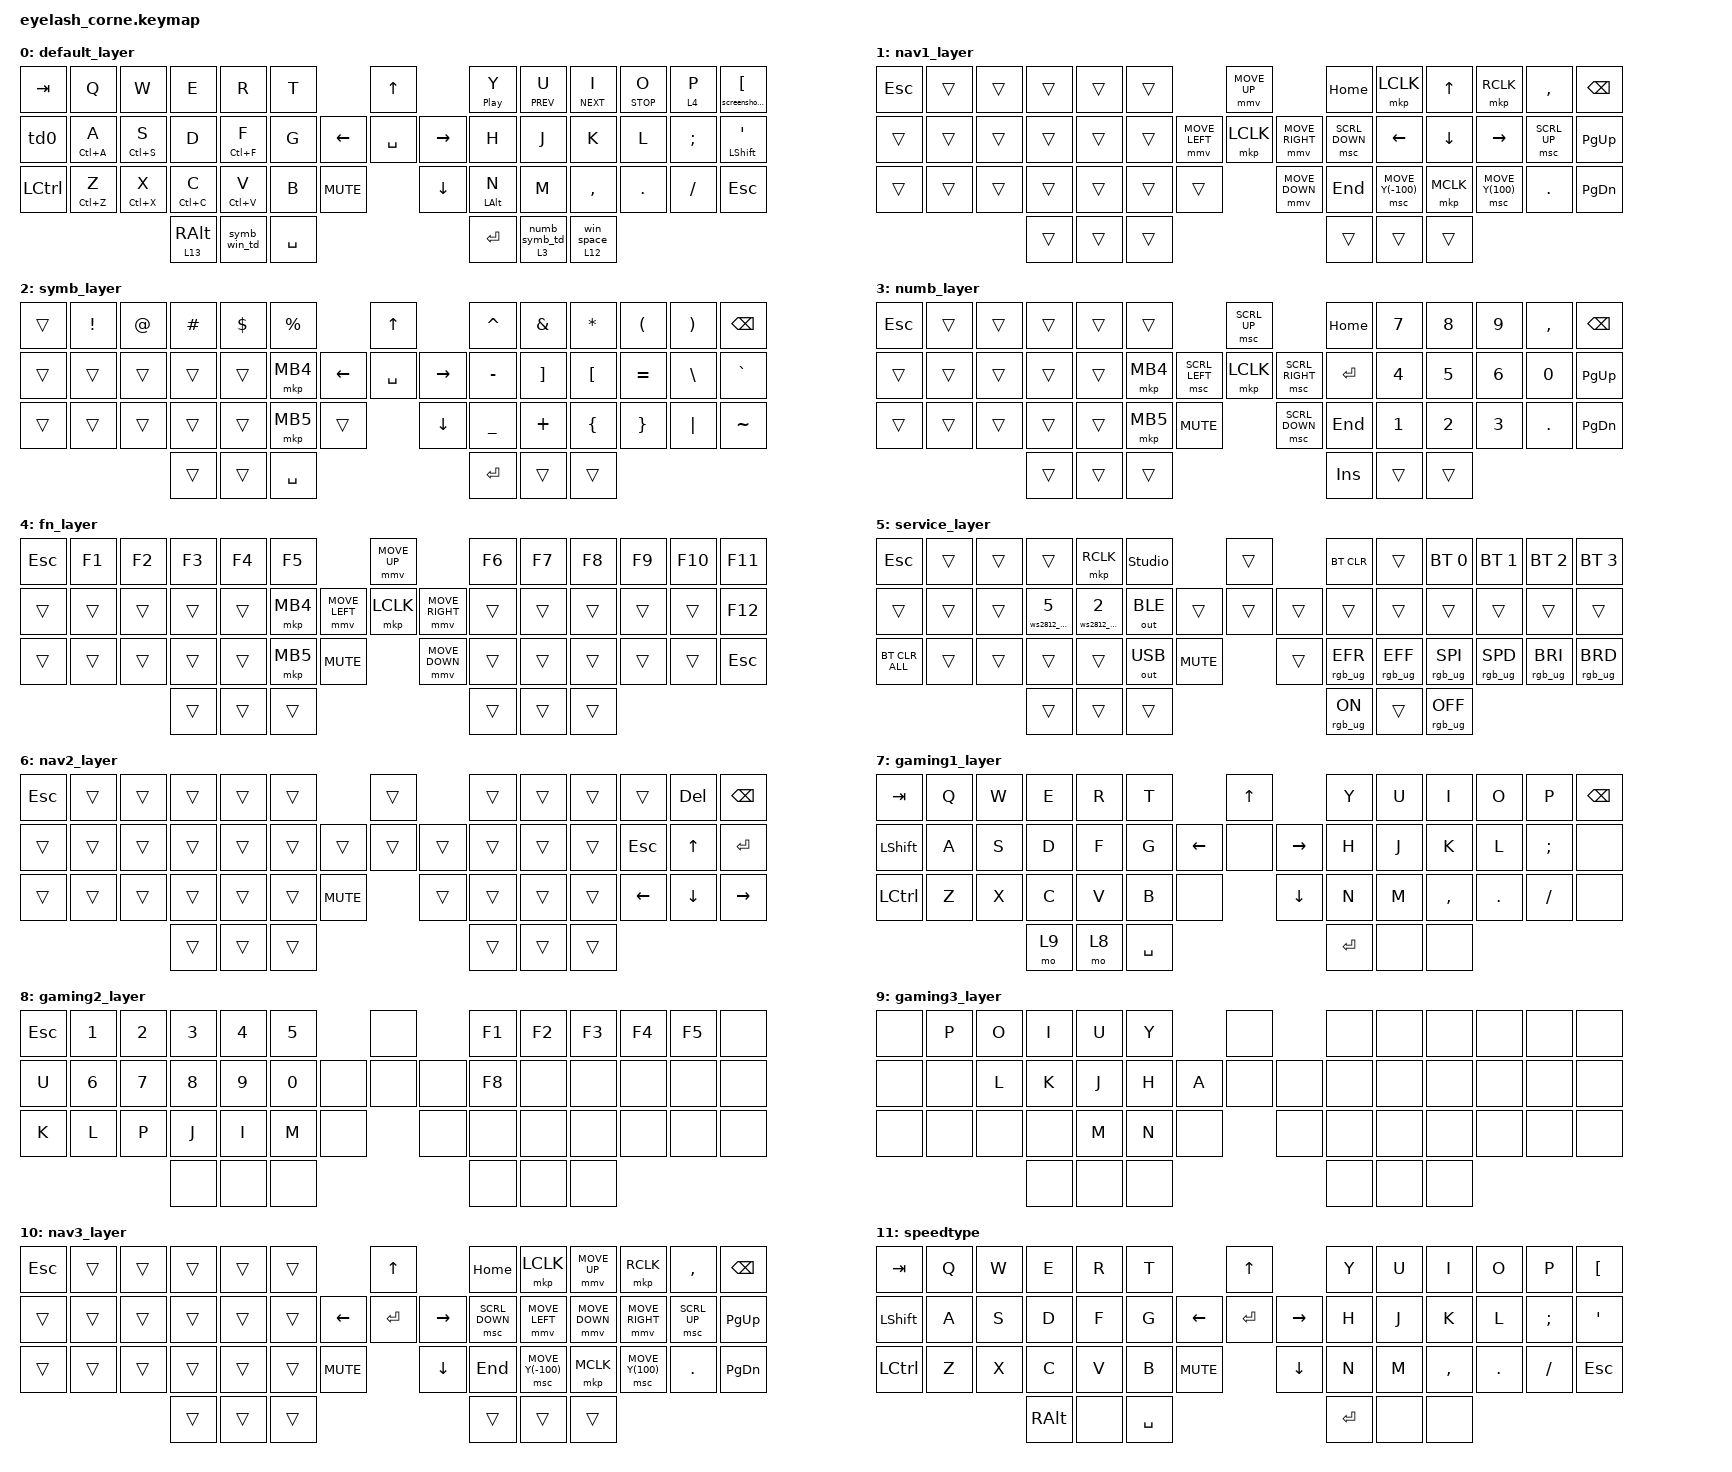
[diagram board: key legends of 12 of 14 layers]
#define ZMK_POINTING_DEFAULT_MOVE_VAL 1200
#define ZMK_POINTING_DEFAULT_SCRL_VAL 25

#include <input/processors.dtsi>
#include <zephyr/dt-bindings/input/input-event-codes.h>
#include <behaviors.dtsi>
#include <behaviors/ws2812_widget.dtsi>
#include <behaviors/ws2812_layer_sync.dtsi>
#include <dt-bindings/zmk/bt.h>
#include <dt-bindings/zmk/keys.h>
#include <dt-bindings/zmk/outputs.h>
#include <dt-bindings/zmk/pointing.h>
#include <dt-bindings/zmk/rgb.h>

&led_strip {
    chain-length = <42>;
};

&mmv_input_listener { input-processors = <&zip_xy_scaler 2 1>; };
&msc_input_listener { input-processors = <&zip_scroll_scaler 2 1>; };

&msc {
    acceleration-exponent = <1>;
    time-to-max-speed-ms = <100>;
    delay-ms = <0>;
};

&mmv {
    time-to-max-speed-ms = <500>;
    acceleration-exponent = <1>;
    trigger-period-ms = <16>;
};

/ {
    chosen {
        zmk,ws2812-widget = &led_strip;
    };

    behaviors {
        td0: td0 {
            compatible = "zmk,behavior-tap-dance";
            #binding-cells = <0>;
            bindings = <&kp LEFT_SHIFT>, <&kp CAPS>;
        };

        numb_symb_td: numb_symb_td {
            compatible = "zmk,behavior-tap-dance";
            #binding-cells = <0>;
            tapping-term-ms = <300>;
            bindings = <&tog 3>, <&tog 2>;
        };

        // Предпоследняя кнопка: Hold = слой цифр (3), Tap = tog цифры/символы
        thumb_num_sym_fn: thumb_num_sym_fn {
            compatible = "zmk,behavior-hold-tap";
            #binding-cells = <2>;
            flavor = "hold-preferred";
            tapping-term-ms = <200>;
            require-prior-idle-ms = <150>;
            bindings = <&mo>, <&numb_symb_td>;
        };

        // Последняя кнопка: Hold = nav2nolight (слой 12), Tap = Win+Space
        lang_nav2: lang_nav2 {
            compatible = "zmk,behavior-hold-tap";
            #binding-cells = <2>;
            flavor = "tap-preferred";
            tapping-term-ms = <220>;
            quick-tap-ms = <150>;
            bindings = <&mo>, <&win_space>;
        };

        nav2_double_tap: nav2_double_tap {
            compatible = "zmk,behavior-tap-dance";
            #binding-cells = <0>;
            tapping-term-ms = <300>;
            bindings = <&trans>, <&tog 6>;
        };

        speedtype_double_tap: speedtype_double_tap {
            compatible = "zmk,behavior-tap-dance";
            #binding-cells = <0>;
            tapping-term-ms = <300>;
            bindings = <&trans>, <&tog 11>;
        };

        kp_once: kp_once {
            compatible = "zmk,behavior-macro-one-param";
            #binding-cells = <1>;
            wait-ms = <0>;
            tap-ms = <0>;
            bindings = <&macro_param_1to1 &macro_press &kp 0>,
                       <&macro_param_1to1 &macro_release &kp 0>;
        };

        edit_ht: edit_ht {
            compatible = "zmk,behavior-hold-tap";
            #binding-cells = <2>;
            flavor = "tap-preferred";
            tapping-term-ms = <220>;
            quick-tap-ms = <150>;
            bindings = <&kp_once>, <&kp>;
        };

        media_ht: media_ht {
            compatible = "zmk,behavior-hold-tap";
            #binding-cells = <2>;
            flavor = "tap-preferred";
            tapping-term-ms = <200>;
            quick-tap-ms = <120>;
            bindings = <&kp>, <&kp>;
        };

        lang_alt: lang_alt {
            compatible = "zmk,behavior-hold-tap";
            #binding-cells = <2>;
            flavor = "tap-preferred";
            tapping-term-ms = <220>;
            quick-tap-ms = <150>;
            bindings = <&kp>, <&kp>;
        };

        // Вторая кнопка слева снизу: Hold = слой символов, Double tap = Windows
        symb_win_td: symb_win_td {
            compatible = "zmk,behavior-tap-dance";
            #binding-cells = <0>;
            tapping-term-ms = <300>;
            bindings = <&mo 2>, <&kp LGUI>;
        };

        // P: Hold = FN слой (4), Tap = буква P
        p_fn_ht: p_fn_ht {
            compatible = "zmk,behavior-hold-tap";
            #binding-cells = <2>;
            flavor = "hold-preferred";
            tapping-term-ms = <200>;
            bindings = <&mo>, <&kp>;
        };

        // Самая левая снизу: Hold = lefthand (13), Tap = RAlt
        lefthand_ht: lefthand_ht {
            compatible = "zmk,behavior-hold-tap";
            #binding-cells = <2>;
            flavor = "hold-preferred";
            tapping-term-ms = <200>;
            require-prior-idle-ms = <150>;
            bindings = <&mo>, <&kp>;
        };

        screenshot_win_shift_s: screenshot_win_shift_s {
            compatible = "zmk,behavior-macro";
            #binding-cells = <0>;
            wait-ms = <0>;
            tap-ms = <30>;
            bindings =
                <&macro_press &kp LGUI>,
                <&macro_press &kp LSHIFT>,
                <&macro_tap &kp S>,
                <&macro_release &kp LSHIFT>,
                <&macro_release &kp LGUI>;
        };

        lbkt_screenshot: lbkt_screenshot {
            compatible = "zmk,behavior-hold-tap";
            #binding-cells = <2>;
            flavor = "tap-preferred";
            tapping-term-ms = <220>;
            quick-tap-ms = <150>;
            bindings = <&screenshot_win_shift_s>, <&kp>;
        };

        win_space: win_space {
            compatible = "zmk,behavior-macro";
            #binding-cells = <0>;
            wait-ms = <0>;
            tap-ms = <0>;
            bindings =
                <&macro_press &kp LGUI>,
                <&macro_tap &kp SPACE>,
                <&macro_release &kp LGUI>;
        };
    };

    combos {
        compatible = "zmk,combos";

        combo_wert_gaming_toggle {
            timeout-ms = <120>;
            require-prior-idle-ms = <250>;
            key-positions = <2 3 4 5>;
            bindings = <&tog 7>;
            layers = <0 7>;
        };

        combo_er_nav3 {
            timeout-ms = <50>;
            key-positions = <3 4>;
            bindings = <&mo 10>;
            layers = <0>;
        };

        combo_sqt_esc_speedtype {
            timeout-ms = <70>;
            key-positions = <27 41>;
            bindings = <&speedtype_double_tap>;
            layers = <0 11>;
        };

        combo_fd_nav {
            timeout-ms = <50>;
            key-positions = <16 17>;
            bindings = <&mo 1>;
            layers = <0 11>;
        };

        combo_service {
            timeout-ms = <50>;
            key-positions = <42 43>;
            bindings = <&mo 5>;
            layers = <0>;
        };

        combo_yu_nav2_double_tap {
            timeout-ms = <50>;
            key-positions = <7 8>;
            bindings = <&nav2_double_tap>;
            layers = <0 1 2 3 4 5 6 11>;
        };

        combo_jk_backspace {
            timeout-ms = <50>;
            key-positions = <23 24>;
            bindings = <&kp BSPC>;
            layers = <0 1 2 3 4 5 6 11>;
        };

        combo_kl_delete {
            timeout-ms = <50>;
            key-positions = <24 25>;
            bindings = <&kp DEL>;
            layers = <0 1 2 3 4 5 6 11>;
        };
    };

    keymap {
        compatible = "zmk,keymap";

        default_layer {
            bindings = <
&kp TAB    &kp Q             &kp W             &kp E             &kp R             &kp T                               &kp UP                 &media_ht C_PP Y    &media_ht C_PREV U  &media_ht C_NEXT I  &media_ht C_STOP O  &p_fn_ht 4 P    &lbkt_screenshot 0 LBKT
&td0       &edit_ht LC(A) A  &edit_ht LC(S) S  &kp D             &edit_ht LC(F) F  &kp G                     &kp LEFT  &kp SPC    &kp RIGHT   &kp H               &kp J               &kp K               &kp L               &kp SEMI        &mt LSHFT SQT
&kp LCTRL  &edit_ht LC(Z) Z  &edit_ht LC(X) X  &edit_ht LC(C) C  &edit_ht LC(V) V  &kp B      &kp C_MUTE               &kp DOWN               &lang_alt LALT N    &kp M               &kp COMMA           &kp DOT             &kp FSLH        &kp ESC
                                               &lefthand_ht 13 RALT  &symb_win_td  &kp SPC                                                    &kp ENTER           &thumb_num_sym_fn 3 0  &lang_nav2 12 0
            >;
            sensor-bindings = <&inc_dec_kp C_VOLUME_UP C_VOLUME_DOWN>;
        };

        nav1_layer {
            bindings = <
&kp ESC  &trans  &trans  &trans  &trans  &trans                             &mmv MOVE_UP                       &kp HOME          &mkp LCLK          &kp UP     &mkp RCLK         &kp COMMA       &kp BSPC
&trans   &trans  &trans  &trans  &trans  &trans             &mmv MOVE_LEFT  &mkp LCLK      &mmv MOVE_RIGHT     &msc SCRL_DOWN    &kp LEFT           &kp DOWN   &kp RIGHT         &msc SCRL_UP    &kp PG_UP
&trans   &trans  &trans  &trans  &trans  &trans  &trans                     &mmv MOVE_DOWN                     &kp END           &msc MOVE_Y(-100)  &mkp MCLK  &msc MOVE_Y(100)  &kp DOT         &kp PG_DN
                         &trans  &trans  &trans                                                                &trans            &trans             &trans
            >;
            // Энкодер: горизонтальный скролл страницы
            sensor-bindings = <&inc_dec_kp PG_UP PG_DN>;
        };

        symb_layer {
            bindings = <
&trans  &kp EXCL  &kp AT  &kp HASH  &kp DLLR  &kp PRCNT                               &kp UP                   &kp CARET  &kp AMPS  &kp ASTRK  &kp LPAR  &kp RPAR  &kp BSPC
&trans  &trans    &trans  &trans    &trans    &mkp MB4                      &kp LEFT  &kp SPC    &kp RIGHT      &kp MINUS  &kp RBKT  &kp LBKT   &kp EQUAL &kp BSLH  &kp GRAVE
&trans  &trans    &trans  &trans    &trans    &mkp MB5   &trans                       &kp DOWN                  &kp UNDER  &kp PLUS  &kp LBRC   &kp RBRC  &kp PIPE  &kp TILDE
                          &trans    &trans    &kp SPC                                                           &kp RET    &trans    &trans
            >;
            sensor-bindings = <&inc_dec_kp C_VOLUME_UP C_VOLUME_DOWN>;
        };

        numb_layer {
            bindings = <
&kp ESC  &trans  &trans  &trans  &trans  &trans                                   &msc SCRL_UP                     &kp HOME   &kp N7  &kp N8  &kp N9  &kp COMMA  &kp BSPC
&trans   &trans  &trans  &trans  &trans  &mkp MB4               &msc SCRL_LEFT    &mkp LCLK     &msc SCRL_RIGHT    &kp ENTER  &kp N4  &kp N5  &kp N6  &kp N0     &kp PG_UP
&trans   &trans  &trans  &trans  &trans  &mkp MB5  &kp C_MUTE                     &msc SCRL_DOWN                   &kp END    &kp N1  &kp N2  &kp N3  &kp DOT    &kp PG_DN
                         &trans  &trans  &trans                                                                    &kp INS    &trans  &trans
            >;
            sensor-bindings = <&inc_dec_kp C_VOLUME_UP C_VOLUME_DOWN>;
        };

        fn_layer {
            bindings = <
&kp ESC  &kp F1  &kp F2  &kp F3  &kp F4  &kp F5                                   &mmv MOVE_UP                       &kp F6  &kp F7  &kp F8  &kp F9  &kp F10  &kp F11
&trans   &trans  &trans  &trans  &trans  &mkp MB4               &mmv MOVE_LEFT    &mkp LCLK       &mmv MOVE_RIGHT    &trans  &trans  &trans  &trans  &trans   &kp F12
&trans   &trans  &trans  &trans  &trans  &mkp MB5  &kp C_MUTE                     &mmv MOVE_DOWN                     &trans  &trans  &trans  &trans  &trans   &kp ESC
                         &trans  &trans  &trans                                                                      &trans  &trans  &trans
            >;
            sensor-bindings = <&inc_dec_kp C_VOLUME_UP C_VOLUME_DOWN>;
        };

        service_layer {
            bindings = <
&kp ESC         &trans  &trans        &trans         &mkp RCLK  &studio_unlock                        &trans              &bt BT_CLR      &trans          &bt BT_SEL 0    &bt BT_SEL 1    &bt BT_SEL 2     &bt BT_SEL 3
&trans          &trans  &trans        &ws2812_wdg 5  &ws2812_wdg 2  &out OUT_BLE          &trans  &trans  &trans       &trans          &trans          &trans          &trans          &trans           &trans
&bt BT_CLR_ALL  &trans  &trans        &trans         &trans     &out OUT_USB  &kp C_MUTE            &trans              &rgb_ug RGB_EFR &rgb_ug RGB_EFF &rgb_ug RGB_SPI &rgb_ug RGB_SPD &rgb_ug RGB_BRI  &rgb_ug RGB_BRD
                                &trans  &trans  &trans                                                        &rgb_ug RGB_ON  &trans          &rgb_ug RGB_OFF
            >;
            sensor-bindings = <&inc_dec_kp C_VOLUME_UP C_VOLUME_DOWN>;
        };

        nav2_layer {
            bindings = <
&kp ESC &trans  &trans  &trans  &trans  &trans                      &trans          &trans  &trans  &trans  &trans    &kp DEL   &kp BSPC
&trans  &trans  &trans  &trans  &trans  &trans          &trans  &trans  &trans      &trans  &trans  &trans  &kp ESC   &kp UP    &kp ENTER
&trans  &trans  &trans  &trans  &trans  &trans  &kp C_MUTE          &trans          &trans  &trans  &trans  &kp LEFT  &kp DOWN  &kp RIGHT
                        &trans  &trans  &trans                                      &trans  &trans  &trans
            >;
            sensor-bindings = <&inc_dec_kp C_VOLUME_UP C_VOLUME_DOWN>;
        };

        gaming1_layer {
            bindings = <
&kp TAB    &kp Q  &kp W  &kp E   &kp R   &kp T                       &kp UP               &kp Y    &kp U   &kp I      &kp O    &kp P     &kp BACKSPACE
&kp LSHFT  &kp A  &kp S  &kp D   &kp F   &kp G           &kp LEFT  &none    &kp RIGHT      &kp H    &kp J   &kp K      &kp L    &kp SEMI  &none
&kp LCTRL  &kp Z  &kp X  &kp C   &kp V   &kp B   &none              &kp DOWN               &kp N    &kp M   &kp COMMA  &kp DOT  &kp FSLH  &none
                          &mo 9   &mo 8   &kp SPACE                                         &kp RET  &none   &none
            >;
            sensor-bindings = <&inc_dec_kp C_VOLUME_UP C_VOLUME_DOWN>;
        };

        gaming2_layer {
            bindings = <
&kp ESC  &kp N1  &kp N2  &kp N3  &kp N4  &kp N5                  &none          &kp F1  &kp F2  &kp F3  &kp F4  &kp F5  &none
&kp U    &kp N6  &kp N7  &kp N8  &kp N9  &kp N0          &none  &none  &none    &kp F8  &none   &none   &none   &none   &none
&kp K    &kp L   &kp P   &kp J   &kp I   &kp M   &none           &none          &none   &none   &none   &none   &none   &none
                          &none   &none   &none                                  &none   &none   &none
            >;
            sensor-bindings = <&inc_dec_kp C_VOLUME_UP C_VOLUME_DOWN>;
        };

        gaming3_layer {
            bindings = <
&none  &kp P  &kp O  &kp I  &kp U  &kp Y                   &none          &none  &none  &none  &none  &none  &none
&none  &none  &kp L  &kp K  &kp J  &kp H           &kp A  &none  &none    &none  &none  &none  &none  &none  &none
&none  &none  &none  &none  &kp M  &kp N   &none           &none          &none  &none  &none  &none  &none  &none
                     &none  &none  &none                                   &none  &none  &none
            >;
            sensor-bindings = <&inc_dec_kp C_VOLUME_UP C_VOLUME_DOWN>;
        };

        nav3_layer {
            bindings = <
&kp ESC &trans  &trans  &trans  &trans  &trans                      &kp UP                 &kp HOME        &mkp LCLK         &mmv MOVE_UP    &mkp RCLK         &kp COMMA      &kp BSPC
&trans  &trans  &trans  &trans  &trans  &trans          &kp LEFT  &kp ENTER  &kp RIGHT     &msc SCRL_DOWN  &mmv MOVE_LEFT    &mmv MOVE_DOWN  &mmv MOVE_RIGHT   &msc SCRL_UP   &kp PG_UP
&trans  &trans  &trans  &trans  &trans  &trans  &kp C_MUTE          &kp DOWN               &kp END         &msc MOVE_Y(-100) &mkp MCLK       &msc MOVE_Y(100)  &kp DOT        &kp PG_DN
                        &trans  &trans  &trans                                             &trans          &trans            &trans
            >;
            // Энкодер: горизонтальный скролл страницы
            sensor-bindings = <&inc_dec_kp PG_UP PG_DN>;
        };

        speedtype {
            bindings = <
&kp TAB    &kp Q  &kp W  &kp E      &kp R   &kp T                               &kp UP                 &kp Y      &kp U      &kp I      &kp O    &kp P     &kp LBKT
&kp LSHFT  &kp A  &kp S  &kp D      &kp F   &kp G                     &kp LEFT  &kp ENTER  &kp RIGHT   &kp H      &kp J      &kp K      &kp L    &kp SEMI  &kp SQT
&kp LCTRL  &kp Z  &kp X  &kp C      &kp V   &kp B      &kp C_MUTE               &kp DOWN               &kp N      &kp M      &kp COMMA  &kp DOT  &kp FSLH  &kp ESC
                          &kp RALT  &none   &kp SPC                                                     &kp ENTER  &none      &none
            >;
            sensor-bindings = <&inc_dec_kp C_VOLUME_UP C_VOLUME_DOWN>;
        };

        nav2nolight_layer {
            bindings = <
&kp ESC &trans  &trans  &trans  &trans  &trans                      &trans          &trans  &trans  &trans  &trans    &kp DEL   &kp BSPC
&trans  &trans  &trans  &trans  &trans  &trans          &trans  &trans  &trans      &trans  &trans  &trans  &kp ESC   &kp UP    &kp ENTER
&trans  &trans  &trans  &trans  &trans  &trans  &kp C_MUTE          &trans          &trans  &trans  &trans  &kp LEFT  &kp DOWN  &kp RIGHT
                        &trans  &trans  &trans                                      &trans  &trans  &trans
            >;
            sensor-bindings = <&inc_dec_kp C_VOLUME_UP C_VOLUME_DOWN>;
        };

        lefthand_layer {
            bindings = <
&trans  &trans  &trans  &trans  &trans  &trans                      &trans          &trans  &trans  &trans  &trans  &trans  &trans
&trans  &trans  &trans  &trans  &trans  &trans          &trans  &trans  &trans      &trans  &trans  &trans  &trans  &trans  &trans
&trans  &trans  &trans  &trans  &trans  &trans  &trans              &trans          &trans  &trans  &trans  &trans  &trans  &trans
                        &trans  &trans  &trans                                      &trans  &trans  &trans
            >;
            sensor-bindings = <&inc_dec_kp C_VOLUME_UP C_VOLUME_DOWN>;
        };
    };
};
